# ATmega2564RFR2 register map
Vendor: Atmel; File version: 1.0
CPU: other r0p0, little endian, no MPU, no FPU, 4 interrupt priority bits
Registers are 8-bit, read-write, reset 0x0 unless marked. A register's access mark holds for its fields unless they carry their own. Offsets are from the block's base; [hi:lo] are bit positions; {n}, {i} and the like mark numbered series.

## TWI — Two Wire Serial Interface
Base 0x000000B8
0x00 TWBR — TWI Bit Rate Register
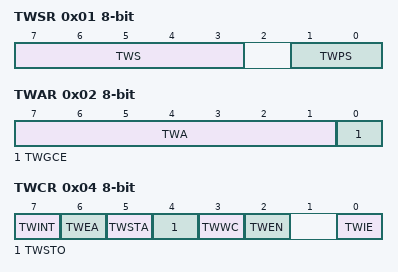
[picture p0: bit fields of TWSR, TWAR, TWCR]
0x01 TWSR — TWI Status Register
  [7:3] TWS — TWI Status
    0=Bus error due to illegal START or STOP condition; 8=A START condition has been transmitted; 16=A repeated START condition has been transmitted; 24=SLA+W has been transmitted; ACK has been received
  [1:0] TWPS — TWI Prescaler Bits
    0=1; 1=4; 2=16; 3=64
0x02 TWAR — TWI (Slave) Address Register
  [7:1] TWA — TWI (Slave) Address
  [0] TWGCE — TWI General Call Recognition Enable Bit
0x03 TWDR — TWI Data Register
0x04 TWCR — TWI Control Register
  [7] TWINT — TWI Interrupt Flag
  [6] TWEA — TWI Enable Acknowledge Bit
  [5] TWSTA — TWI START Condition Bit
  [4] TWSTO — TWI STOP Condition Bit
  [3] TWWC — TWI Write Collision Flag
  [2] TWEN — TWI Enable Bit
  [0] TWIE — TWI Interrupt Enable
0x05 TWAMR — TWI (Slave) Address Mask Register
  [7:1] TWAM — TWI Address Mask

## USART0 — USART
Base 0x000000C0
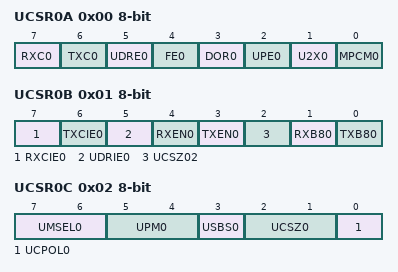
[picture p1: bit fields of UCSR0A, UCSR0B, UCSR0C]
0x00 UCSR0A — USART0 Control and Status Register A
  [7] RXC0 — USART Receive Complete
  [6] TXC0 — USART Transmit Complete
  [5] UDRE0 — USART Data Register Empty
  [4] FE0 — Frame Error
  [3] DOR0 — Data OverRun
  [2] UPE0 — USART Parity Error
  [1] U2X0 — Double the USART Transmission Speed
  [0] MPCM0 — Multi-processor Communication Mode
0x01 UCSR0B — USART0 Control and Status Register B
  [7] RXCIE0 — RX Complete Interrupt Enable
  [6] TXCIE0 — TX Complete Interrupt Enable
  [5] UDRIE0 — USART Data Register Empty Interrupt Enable
  [4] RXEN0 — Receiver Enable
  [3] TXEN0 — Transmitter Enable
  [2] UCSZ02 — Character Size
  [1] RXB80 — Receive Data Bit 8
  [0] TXB80 — Transmit Data Bit 8
0x02 UCSR0C — USART0 Control and Status Register C
  [7:6] UMSEL0 — USART Mode Select
    0=Asynchronous USART; 1=Synchronous USART; 3=Master SPI (MSPIM)
  [5:4] UPM0 — Parity Mode
    0=Disabled; 2=Enabled, Even Parity; 3=Enabled, Odd Parity
  [3] USBS0 — Stop Bit Select
    0=1-bit; 1=2-bit
  [2:1] UCSZ0 — Character Size
    {v}={v+5}-bit (v=0..3)
  [0] UCPOL0 — Clock Polarity
    0=Rising XCKn Edge (Transmitted Data Changed), Falling XCKn Edge (Received Data Sampled); 1=Falling XCKn Edge (Transmitted Data Changed), Rising XCKn Edge (Received Data Sampled)
0x04 UBRR0 16-bit (reset mask 0xFF) — USART0 Baud Rate Register Bytes
0x06 UDR0 — USART0 I/O Data Register

## USART0_SPI — Serial Peripheral Interface
Base 0x000000C0
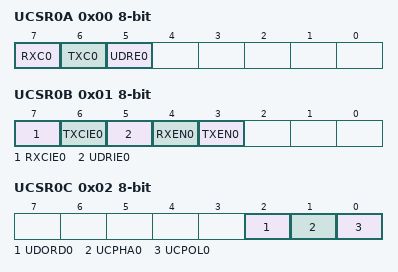
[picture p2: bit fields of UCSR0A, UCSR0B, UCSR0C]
0x00 UCSR0A — USART0 MSPIM Control and Status Register A
  [7] RXC0 — USART Receive Complete
  [6] TXC0 — USART Transmit Complete
  [5] UDRE0 — USART Data Register Empty
0x01 UCSR0B — USART0 MSPIM Control and Status Register B
  [7] RXCIE0 — RX Complete Interrupt Enable
  [6] TXCIE0 — TX Complete Interrupt Enable
  [5] UDRIE0 — USART Data Register Empty Interrupt Enable
  [4] RXEN0 — Receiver Enable
  [3] TXEN0 — Transmitter Enable
0x02 UCSR0C — USART0 MSPIM Control and Status Register C
  [2] UDORD0 — Data Order
  [1] UCPHA0 — Clock Phase
  [0] UCPOL0 — Clock Polarity

## USART1 — USART
Base 0x000000C8
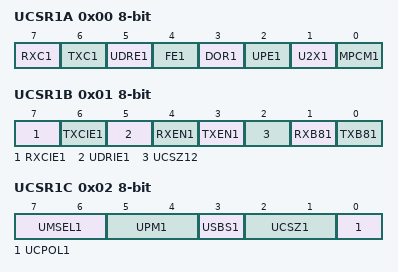
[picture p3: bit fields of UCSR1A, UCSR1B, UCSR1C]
0x00 UCSR1A — USART1 Control and Status Register A
  [7] RXC1 — USART Receive Complete
  [6] TXC1 — USART Transmit Complete
  [5] UDRE1 — USART Data Register Empty
  [4] FE1 — Frame Error
  [3] DOR1 — Data OverRun
  [2] UPE1 — USART Parity Error
  [1] U2X1 — Double the USART Transmission Speed
  [0] MPCM1 — Multi-processor Communication Mode
0x01 UCSR1B — USART1 Control and Status Register B
  [7] RXCIE1 — RX Complete Interrupt Enable
  [6] TXCIE1 — TX Complete Interrupt Enable
  [5] UDRIE1 — USART Data Register Empty Interrupt Enable
  [4] RXEN1 — Receiver Enable
  [3] TXEN1 — Transmitter Enable
  [2] UCSZ12 — Character Size
  [1] RXB81 — Receive Data Bit 8
  [0] TXB81 — Transmit Data Bit 8
0x02 UCSR1C — USART1 Control and Status Register C
  [7:6] UMSEL1 — USART Mode Select
    0=Asynchronous USART; 1=Synchronous USART; 3=Master SPI (MSPIM)
  [5:4] UPM1 — Parity Mode
    0=Disabled; 2=Enabled, Even Parity; 3=Enabled, Odd Parity
  [3] USBS1 — Stop Bit Select
    0=1-bit; 1=2-bit
  [2:1] UCSZ1 — Character Size
    {v}={v+5}-bit (v=0..3)
  [0] UCPOL1 — Clock Polarity
    0=Rising XCKn Edge (Transmitted Data Changed), Falling XCKn Edge (Received Data Sampled); 1=Falling XCKn Edge (Transmitted Data Changed), Rising XCKn Edge (Received Data Sampled)
0x04 UBRR1 16-bit (reset mask 0xFF) — USART1 Baud Rate Register Bytes
0x06 UDR1 — USART1 I/O Data Register

## USART1_SPI — Serial Peripheral Interface
Base 0x000000C8
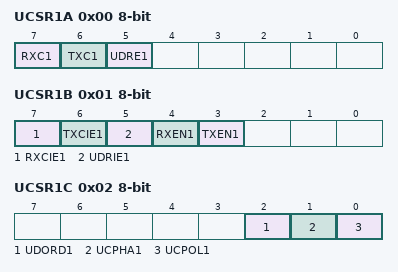
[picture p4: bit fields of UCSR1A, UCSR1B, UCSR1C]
0x00 UCSR1A — USART1 MSPIM Control and Status Register A
  [7] RXC1 — USART Receive Complete
  [6] TXC1 — USART Transmit Complete
  [5] UDRE1 — USART Data Register Empty
0x01 UCSR1B — USART1 MSPIM Control and Status Register B
  [7] RXCIE1 — RX Complete Interrupt Enable
  [6] TXCIE1 — TX Complete Interrupt Enable
  [5] UDRIE1 — USART Data Register Empty Interrupt Enable
  [4] RXEN1 — Receiver Enable
  [3] TXEN1 — Transmitter Enable
0x02 UCSR1C — USART1 MSPIM Control and Status Register C
  [2] UDORD1 — Data Order
  [1] UCPHA1 — Clock Phase
  [0] UCPOL1 — Clock Polarity

## WDT — Watchdog Timer
Base 0x00000060
0x00 WDTCSR — Watchdog Timer Control Register
  [7] WDIF — Watchdog Timeout Interrupt Flag
  [6] WDIE — Watchdog Timeout Interrupt Enable
  [4] WDCE — Watchdog Change Enable
  [3] WDE — Watch Dog Enable
  [5:0] WDP — Watchdog Timer Prescaler Bits
    0=Oscillator Cycles 2K; 1=Oscillator Cycles 4K; 2=Oscillator Cycles 8K; 3=Oscillator Cycles 16K; 4=Oscillator Cycles 32K; 5=Oscillator Cycles 64K; 6=Oscillator Cycles 128K; 7=Oscillator Cycles 256K
